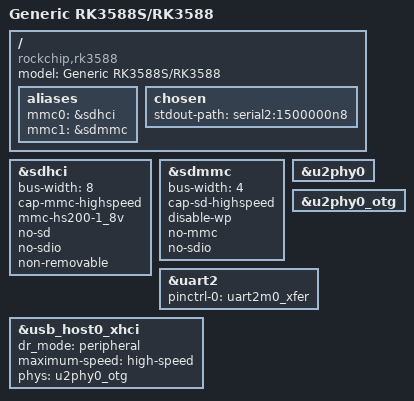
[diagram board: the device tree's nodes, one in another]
// SPDX-License-Identifier: (GPL-2.0+ OR MIT)
/*
 * Minimal generic DT for RK3588S/RK3588 with eMMC, SD-card and USB OTG enabled
 */

/dts-v1/;
#include "rk3588s.dtsi"

/ {
	model = "Generic RK3588S/RK3588";
	compatible = "rockchip,rk3588";

	aliases {
		mmc0 = &sdhci;
		mmc1 = &sdmmc;
	};

	chosen {
		stdout-path = "serial2:1500000n8";
	};
};

&sdhci {
	bus-width = <8>;
	cap-mmc-highspeed;
	mmc-hs200-1_8v;
	no-sd;
	no-sdio;
	non-removable;
	status = "okay";
};

&sdmmc {
	bus-width = <4>;
	cap-sd-highspeed;
	disable-wp;
	no-mmc;
	no-sdio;
	status = "okay";
};

&u2phy0 {
	status = "okay";
};

&u2phy0_otg {
	status = "okay";
};

&uart2 {
	pinctrl-0 = <&uart2m0_xfer>;
	status = "okay";
};

&usb_host0_xhci {
	dr_mode = "peripheral";
	maximum-speed = "high-speed";
	phys = <&u2phy0_otg>;
	phy-names = "usb2-phy";
	status = "okay";
};
